# MS32F031 register map
File version: 1.0
CPU: CM0 r1p0, little endian, no MPU, no FPU, 3 interrupt priority bits
Registers are 32-bit, read-write, reset 0x0 unless marked. A register's access mark holds for its fields unless they carry their own. Offsets are from the block's base; [hi:lo] are bit positions; {n}, {i} and the like mark numbered series.

## TIM14 — General-purpose-timers
Base 0x40002000
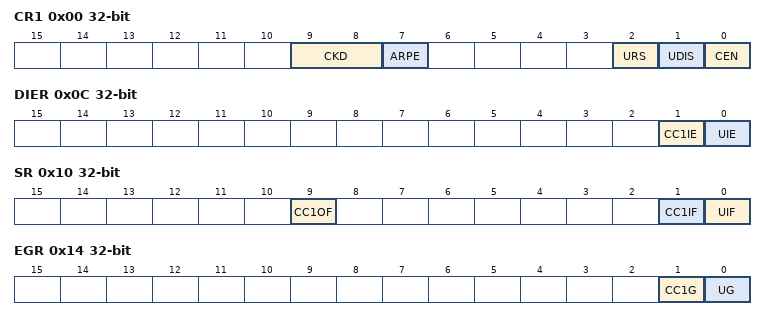
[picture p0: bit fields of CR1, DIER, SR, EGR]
0x00 CR1 — control register 1
  [9:8] CKD — Clock division
  [7] ARPE — Auto-reload preload enable
  [2] URS — Update request source
  [1] UDIS — Update disable
  [0] CEN — Counter enable
0x0C DIER — DMA/Interrupt enable register
  [1] CC1IE — Capture/Compare 1 interrupt enable
  [0] UIE — Update interrupt enable
0x10 SR — status register
  [9] CC1OF — Capture/Compare 1 overcapture flag
  [1] CC1IF — Capture/compare 1 interrupt flag
  [0] UIF — Update interrupt flag
0x14 EGR wo — event generation register
  [1] CC1G — Capture/compare 1 generation
  [0] UG — Update generation
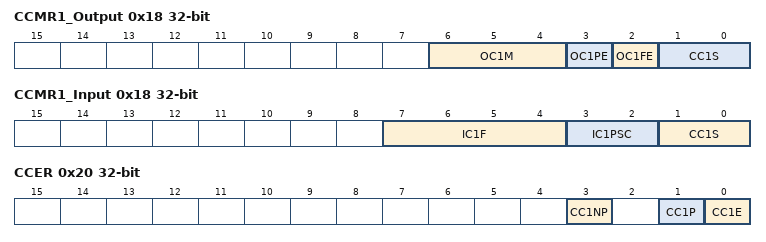
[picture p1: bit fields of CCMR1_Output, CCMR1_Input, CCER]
0x18 CCMR1_Output — capture/compare mode register (output mode)
  [6:4] OC1M — Output Compare 1 mode
  [3] OC1PE — Output Compare 1 preload enable
  [2] OC1FE — Output compare 1 fast enable
  [1:0] CC1S — Capture/Compare 1 selection
0x18 CCMR1_Input (alternate view of CCMR1_Output) — capture/compare mode register (input mode)
  [7:4] IC1F — Input capture 1 filter
  [3:2] IC1PSC — Input capture 1 prescaler
  [1:0] CC1S — Capture/Compare 1 selection
0x20 CCER — capture/compare enable register
  [3] CC1NP — Capture/Compare 1 output Polarity
  [1] CC1P — Capture/Compare 1 output Polarity
  [0] CC1E — Capture/Compare 1 output enable
0x24 CNT — counter
  [15:0] CNT — counter value
0x28 PSC — prescaler
  [15:0] PSC — Prescaler value
0x2C ARR — auto-reload register
  [15:0] ARR — Auto-reload value
0x34 CCR1 — capture/compare register 1
  [15:0] CCR1 — Capture/Compare 1 value
0x50 OR — option register
  [1:0] RMP — Timer input 1 remap

## EXTI — External interrupt/event controller
Base 0x40010400
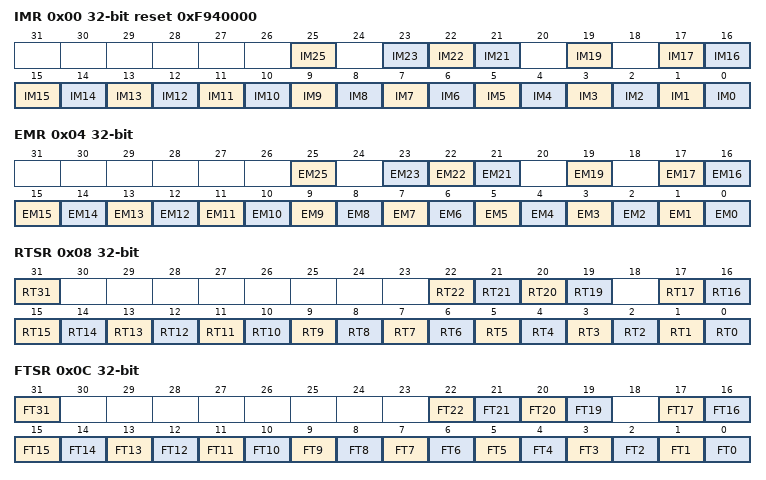
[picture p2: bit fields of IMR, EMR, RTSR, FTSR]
0x00 IMR reset 0xF940000 — Interrupt mask register (EXTI_IMR)
  [25] IM25 — Interrupt Mask on line 25
  [23] IM23 — Interrupt Mask on line 23
  [22] IM22 — Interrupt Mask on line 22
  [21] IM21 — Interrupt Mask on line 21
  [19] IM19 — Interrupt Mask on line 19
  [n] IM{n} (n=0..17) — Interrupt Mask on line {n}
0x04 EMR — Event mask register (EXTI_EMR)
  [25] EM25 — Event Mask on line 25
  [23] EM23 — Event Mask on line 23
  [22] EM22 — Event Mask on line 22
  [21] EM21 — Event Mask on line 21
  [19] EM19 — Event Mask on line 19
  [n] EM{n} (n=0..17) — Event Mask on line {n}
0x08 RTSR — Rising Trigger selection register (EXTI_RTSR)
  [31] RT31 — Rising trigger event configuration of line 31
  [n] RT{n} (n=19..22) — Rising trigger event configuration of line {n}
  [n] RT{n} (n=0..17) — Rising trigger event configuration of line {n}
0x0C FTSR — Falling Trigger selection register (EXTI_FTSR)
  [31] FT31 — Falling trigger event configuration of line 31
  [n] FT{n} (n=19..22) — Falling trigger event configuration of line {n}
  [n] FT{n} (n=0..17) — Falling trigger event configuration of line {n}
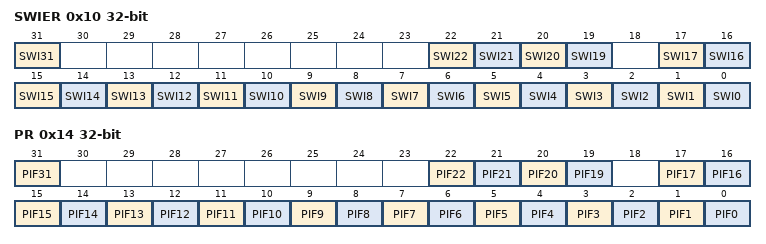
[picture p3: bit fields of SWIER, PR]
0x10 SWIER — Software interrupt event register (EXTI_SWIER)
  [31] SWI31 — Software Interrupt on line 31
  [n] SWI{n} (n=19..22) — Software Interrupt on line {n}
  [n] SWI{n} (n=0..17) — Software Interrupt on line {n}
0x14 PR — Pending register (EXTI_PR)
  [31] PIF31 — Pending bit 31
  [n] PIF{n} (n=19..22) — Pending bit {n}
  [n] PIF{n} (n=0..17) — Pending bit {n}

## NVIC — Nested Vectored Interrupt Controller
Base 0xE000E100
0x00 ISER — Interrupt Set Enable Register
  [31:0] SETENA
0x80 ICER — Interrupt Clear Enable Register
  [31:0] CLRENA
0x100 ISPR — Interrupt Set-Pending Register
  [31:0] SETPEND
0x180 ICPR — Interrupt Clear-Pending Register
  [31:0] CLRPEND
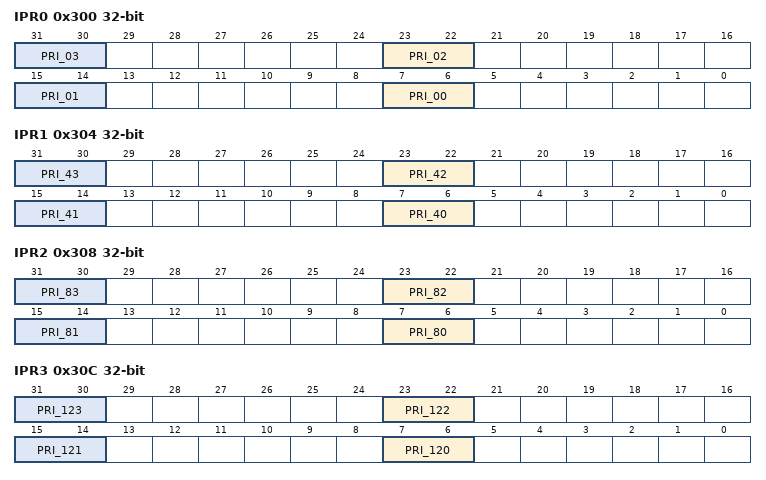
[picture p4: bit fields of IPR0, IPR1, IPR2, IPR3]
0x300 IPR0 — Interrupt Priority Register 0
  [8n+7:8n+6] PRI_{n:02} (n=0..3)
0x304 IPR1 — Interrupt Priority Register 1
  [8n-313:8n-314] PRI_{n} (n=40..43)
0x308 IPR2 — Interrupt Priority Register 2
  [8n-633:8n-634] PRI_{n} (n=80..83)
0x30C IPR3 — Interrupt Priority Register 3
  [8n-953:8n-954] PRI_{n} (n=120..123)
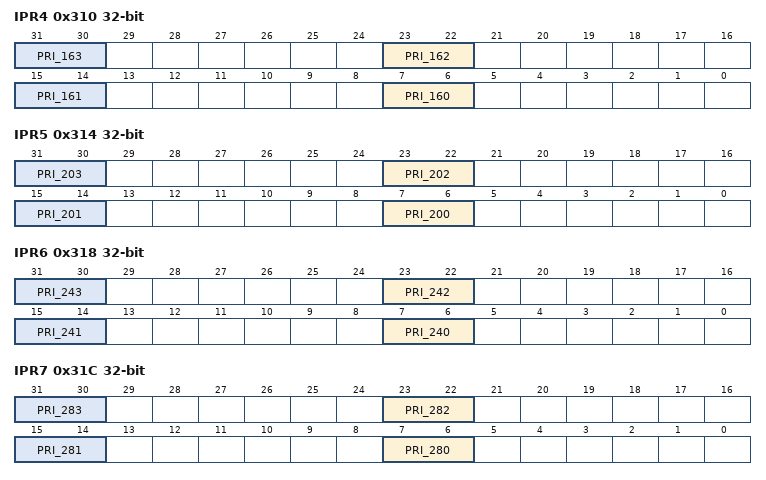
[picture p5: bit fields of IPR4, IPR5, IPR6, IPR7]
0x310 IPR4 — Interrupt Priority Register 4
  [8n-1273:8n-1274] PRI_{n} (n=160..163)
0x314 IPR5 — Interrupt Priority Register 5
  [8n-1593:8n-1594] PRI_{n} (n=200..203)
0x318 IPR6 — Interrupt Priority Register 6
  [8n-1913:8n-1914] PRI_{n} (n=240..243)
0x31C IPR7 — Interrupt Priority Register 7
  [8n-2233:8n-2234] PRI_{n} (n=280..283)
